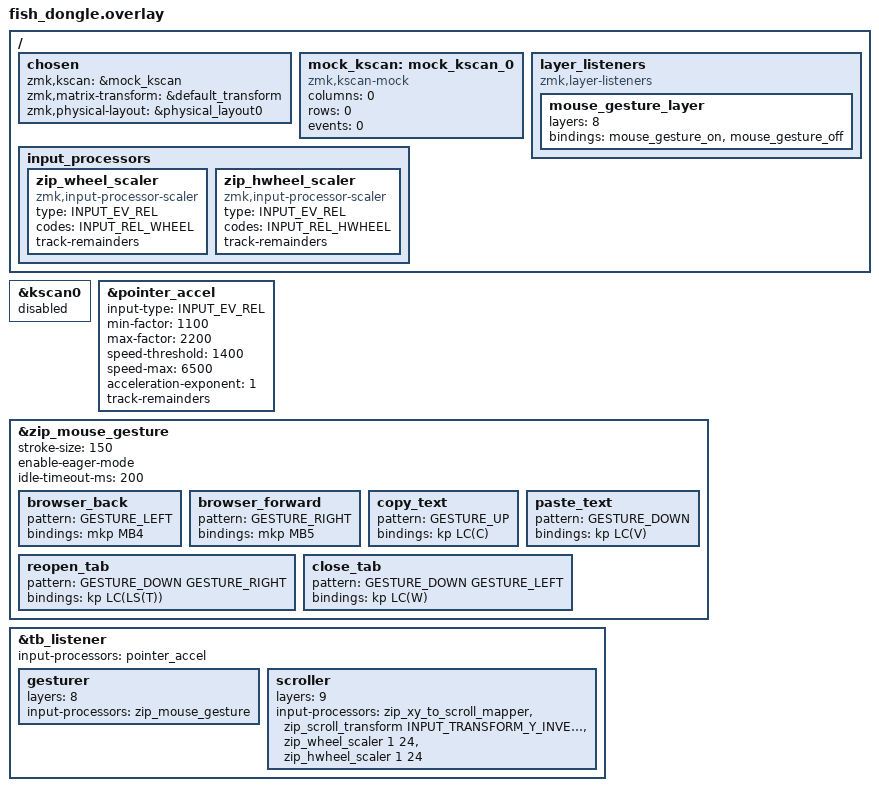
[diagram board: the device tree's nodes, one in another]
#include <dt-bindings/zmk/matrix_transform.h>
#include <dt-bindings/zmk/input_transform.h>
#include <dt-bindings/input/input-event-codes.h>
#include <dt-bindings/zmk/keys.h>
#include <dt-bindings/zmk/pointing.h>
#include <input/processors.dtsi>
#include <behaviors/input_gestures_accel.dtsi>
#include <mouse-gesture.dtsi>

#include "fish.dtsi"
#include "split_input.dtsi"

/ {
    chosen {
        zmk,kscan = &mock_kscan;
        zmk,matrix-transform = &default_transform;
        zmk,physical-layout = &physical_layout0;
    };

    mock_kscan: mock_kscan_0 {
        compatible = "zmk,kscan-mock";
        columns = <0>;
        rows = <0>;
        events = <0>;
    };

    input_processors {
        zip_wheel_scaler: zip_wheel_scaler {
            compatible = "zmk,input-processor-scaler";
            #input-processor-cells = <2>;
            type = <INPUT_EV_REL>;
            codes = <INPUT_REL_WHEEL>;
            track-remainders;
        };

        zip_hwheel_scaler: zip_hwheel_scaler {
            compatible = "zmk,input-processor-scaler";
            #input-processor-cells = <2>;
            type = <INPUT_EV_REL>;
            codes = <INPUT_REL_HWHEEL>;
            track-remainders;
        };
    };

    layer_listeners {
        compatible = "zmk,layer-listeners";

        mouse_gesture_layer {
            layers = <8>;
            bindings = <&mouse_gesture_on &mouse_gesture_off>;
        };
    };
};

&kscan0 {
    status = "disabled";
};

&pointer_accel {
    input-type = <INPUT_EV_REL>;
    min-factor = <1100>;
    max-factor = <2200>;
    speed-threshold = <1400>;
    speed-max = <6500>;
    acceleration-exponent = <1>;
    track-remainders;
};

&zip_mouse_gesture {
    stroke-size = <150>;
    enable-eager-mode;
    idle-timeout-ms = <200>;

    browser_back {
        pattern = <GESTURE_LEFT>;
        bindings = <&mkp MB4>;
    };

    browser_forward {
        pattern = <GESTURE_RIGHT>;
        bindings = <&mkp MB5>;
    };

    copy_text {
        pattern = <GESTURE_UP>;
        bindings = <&kp LC(C)>;
    };

    paste_text {
        pattern = <GESTURE_DOWN>;
        bindings = <&kp LC(V)>;
    };

    reopen_tab {
        pattern = <GESTURE_DOWN GESTURE_RIGHT>;
        bindings = <&kp LC(LS(T))>;
    };

    close_tab {
        pattern = <GESTURE_DOWN GESTURE_LEFT>;
        bindings = <&kp LC(W)>;
    };
};

&tb_listener {
    status = "okay";

    input-processors = <&pointer_accel>;

    gesturer {
        layers = <8>;
        input-processors = <&zip_mouse_gesture>;
    };

    scroller {
        layers = <9>;
        input-processors =
            <&zip_xy_to_scroll_mapper>,
            <&zip_scroll_transform INPUT_TRANSFORM_Y_INVERT>,
            <&zip_wheel_scaler 1 24>,
            <&zip_hwheel_scaler 1 24>;
    };
};
